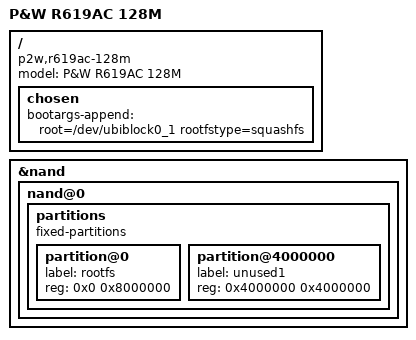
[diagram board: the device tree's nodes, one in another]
// SPDX-License-Identifier: GPL-2.0-or-later OR MIT

#include "qcom-ipq4019-r619ac.dtsi"

/ {
	model = "P&W R619AC 128M";
	compatible = "p2w,r619ac-128m";

	chosen {
		bootargs-append = " root=/dev/ubiblock0_1 rootfstype=squashfs";
	};
};

&nand {
	status = "okay";

	nand@0 {
		partitions {
			compatible = "fixed-partitions";
			#address-cells = <1>;
			#size-cells = <1>;

			partition@0 {
				label = "rootfs";
				reg = <0x0 0x8000000>;
			};

			partition@4000000 {
				label = "unused1";
				reg = <0x4000000 0x4000000>;
			};
		};
	};
};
